# ESP32S31_RADIO register map
Vendor: Espressif; Series: ESP32-S31; File version: 3.52
Registers are 32-bit, read-write, no defined reset value unless marked. A register's access mark holds for its fields unless they carry their own. Offsets are from the block's base; [hi:lo] are bit positions.

## WIFI_MAC_HE_TRIGGER_RX_DIAGNOSTICS — Ten hardware diagnostic words decoded by complete dbg_read_ax_diag. The blob explicitly warns that these words are not latched and can be updated by a following RX frame; consume them only as best-effort diagnostics adjacent to a known Trigger reception.
Base 0x20104508
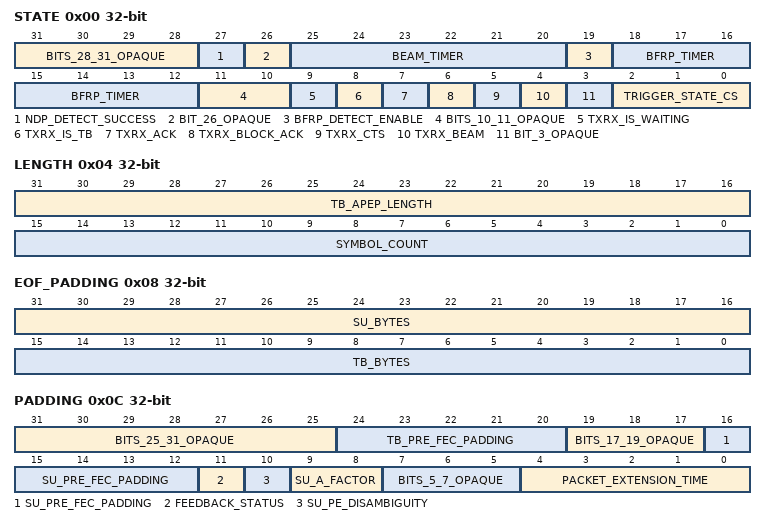
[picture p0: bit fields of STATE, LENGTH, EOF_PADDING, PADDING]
0x00 STATE ro — Project-assigned name. WDEVAXDIAG0.
  [31:28] BITS_28_31_OPAQUE — Opaque: meaning not established.
  [27] NDP_DETECT_SUCCESS — Project-assigned name.
  [26] BIT_26_OPAQUE — Opaque: meaning not established.
  [25:20] BEAM_TIMER — Project-assigned name.
  [19] BFRP_DETECT_ENABLE — Project-assigned name.
  [18:12] BFRP_TIMER — Project-assigned name.
  [11:10] BITS_10_11_OPAQUE — Opaque: meaning not established.
  [9] TXRX_IS_WAITING — Project-assigned name.
  [8] TXRX_IS_TB — Project-assigned name.
  [7] TXRX_ACK — Project-assigned name.
  [6] TXRX_BLOCK_ACK — Project-assigned name.
  [5] TXRX_CTS — Project-assigned name.
  [4] TXRX_BEAM — Project-assigned name.
  [3] BIT_3_OPAQUE — Opaque: meaning not established.
  [2:0] TRIGGER_STATE_CS — Project-assigned name.
0x04 LENGTH ro — Project-assigned name. WDEVAXDIAG1.
  [31:16] TB_APEP_LENGTH — Project-assigned name.
  [15:0] SYMBOL_COUNT — Project-assigned name.
0x08 EOF_PADDING ro — Project-assigned name. WDEVAXDIAG2. Padding bytes exclude the final subframe padding bytes.
  [31:16] SU_BYTES — Project-assigned name.
  [15:0] TB_BYTES — Project-assigned name.
0x0C PADDING ro — Project-assigned name. WDEVAXDIAG3.
  [31:25] BITS_25_31_OPAQUE — Opaque: meaning not established.
  [24:20] TB_PRE_FEC_PADDING — Project-assigned name.
  [19:17] BITS_17_19_OPAQUE — Opaque: meaning not established.
  [16:12] SU_PRE_FEC_PADDING — Project-assigned name.
  [11] FEEDBACK_STATUS — Project-assigned name.
  [10] SU_PE_DISAMBIGUITY — Project-assigned name.
  [9:8] SU_A_FACTOR — Project-assigned name.
  [7:5] BITS_5_7_OPAQUE — Opaque: meaning not established.
  [4:0] PACKET_EXTENSION_TIME — Project-assigned name.
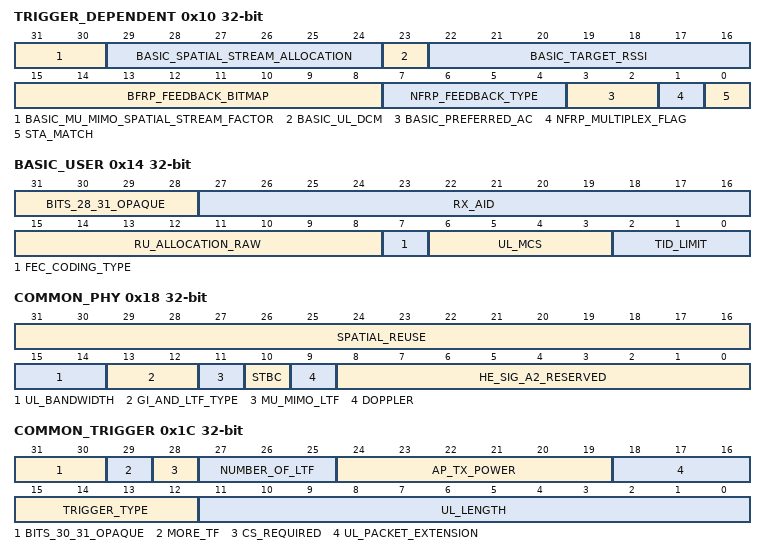
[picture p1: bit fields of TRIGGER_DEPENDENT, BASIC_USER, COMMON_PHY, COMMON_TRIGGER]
0x10 TRIGGER_DEPENDENT ro — Project-assigned name. WDEVAXDIAG4.
  [31:30] BASIC_MU_MIMO_SPATIAL_STREAM_FACTOR — Project-assigned name.
  [29:24] BASIC_SPATIAL_STREAM_ALLOCATION — Project-assigned name.
  [23] BASIC_UL_DCM — Project-assigned name.
  [22:16] BASIC_TARGET_RSSI — Project-assigned name.
  [15:8] BFRP_FEEDBACK_BITMAP — Project-assigned name.
  [7:4] NFRP_FEEDBACK_TYPE — Project-assigned name.
  [3:2] BASIC_PREFERRED_AC — Project-assigned name.
  [1] NFRP_MULTIPLEX_FLAG — Project-assigned name.
  [0] STA_MATCH — Project-assigned name.
0x14 BASIC_USER ro — Project-assigned name. WDEVAXDIAG5.
  [31:28] BITS_28_31_OPAQUE — Opaque: meaning not established.
  [27:16] RX_AID — Project-assigned name.
  [15:8] RU_ALLOCATION_RAW — Project-assigned name.
  [7] FEC_CODING_TYPE — Project-assigned name.
  [6:3] UL_MCS — Project-assigned name.
  [2:0] TID_LIMIT — Project-assigned name.
0x18 COMMON_PHY ro — Project-assigned name. WDEVAXDIAG6.
  [31:16] SPATIAL_REUSE — Project-assigned name.
  [15:14] UL_BANDWIDTH — Project-assigned name.
  [13:12] GI_AND_LTF_TYPE — Project-assigned name.
  [11] MU_MIMO_LTF — Project-assigned name.
  [10] STBC — Project-assigned name.
  [9] DOPPLER — Project-assigned name.
  [8:0] HE_SIG_A2_RESERVED — Project-assigned name.
0x1C COMMON_TRIGGER ro — Project-assigned name. WDEVAXDIAG7.
  [31:30] BITS_30_31_OPAQUE — Opaque: meaning not established.
  [29] MORE_TF — Project-assigned name.
  [28] CS_REQUIRED — Project-assigned name.
  [27:25] NUMBER_OF_LTF — Project-assigned name.
  [24:19] AP_TX_POWER — Project-assigned name.
  [18:16] UL_PACKET_EXTENSION — Project-assigned name.
  [15:12] TRIGGER_TYPE — Project-assigned name.
  [11:0] UL_LENGTH — Project-assigned name.
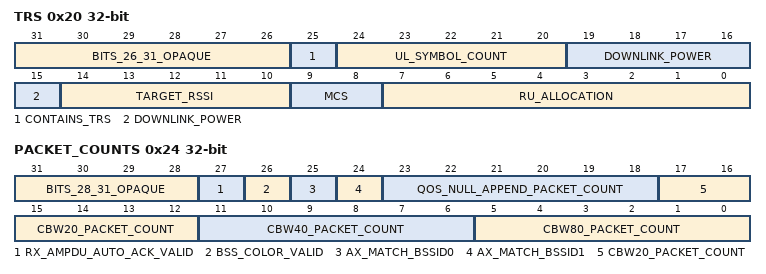
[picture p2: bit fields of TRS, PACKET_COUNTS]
0x20 TRS ro — Project-assigned name. WDEVAXDIAG8.
  [31:26] BITS_26_31_OPAQUE — Opaque: meaning not established.
  [25] CONTAINS_TRS — Project-assigned name.
  [24:20] UL_SYMBOL_COUNT — Project-assigned name.
  [19:15] DOWNLINK_POWER — Project-assigned name.
  [14:10] TARGET_RSSI — Project-assigned name.
  [9:8] MCS — Project-assigned name.
  [7:0] RU_ALLOCATION — Project-assigned name.
0x24 PACKET_COUNTS ro — Project-assigned name. WDEVAXDIAG9.
  [31:28] BITS_28_31_OPAQUE — Opaque: meaning not established.
  [27] RX_AMPDU_AUTO_ACK_VALID — Project-assigned name.
  [26] BSS_COLOR_VALID — Project-assigned name.
  [25] AX_MATCH_BSSID0 — Project-assigned name.
  [24] AX_MATCH_BSSID1 — Project-assigned name.
  [23:18] QOS_NULL_APPEND_PACKET_COUNT — Project-assigned name.
  [17:12] CBW20_PACKET_COUNT — Project-assigned name.
  [11:6] CBW40_PACKET_COUNT — Project-assigned name.
  [5:0] CBW80_PACKET_COUNT — Project-assigned name.
